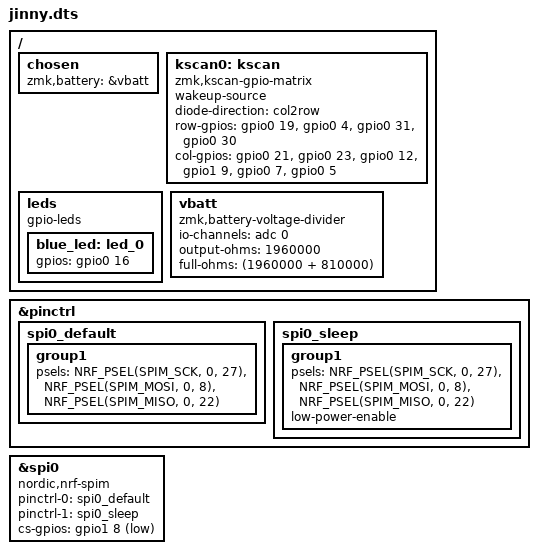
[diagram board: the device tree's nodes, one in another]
/*
*
* Copyright (c) 2021 Darryl deHaan
* SPDX-License-Identifier: MIT
*
*/

#include "jinny.dtsi"

/{
    chosen {
        zmk,battery = &vbatt;
    };

    kscan0: kscan {
        compatible = "zmk,kscan-gpio-matrix";
        wakeup-source;

        diode-direction = "col2row";
        row-gpios
            = <&gpio0 19 (GPIO_ACTIVE_HIGH | GPIO_PULL_DOWN)>
            , <&gpio0  4 (GPIO_ACTIVE_HIGH | GPIO_PULL_DOWN)>
            , <&gpio0 31 (GPIO_ACTIVE_HIGH | GPIO_PULL_DOWN)>
            , <&gpio0 30 (GPIO_ACTIVE_HIGH | GPIO_PULL_DOWN)>
            ;

        col-gpios
            = <&gpio0 21 GPIO_ACTIVE_HIGH>
            , <&gpio0 23 GPIO_ACTIVE_HIGH>
            , <&gpio0 12 GPIO_ACTIVE_HIGH>
            , <&gpio1  9 GPIO_ACTIVE_HIGH>
            , <&gpio0  7 GPIO_ACTIVE_HIGH>
            , <&gpio0  5 GPIO_ACTIVE_HIGH>
            ;
    };

    leds {
        compatible = "gpio-leds";
        blue_led: led_0 {
            gpios = <&gpio0 16 GPIO_ACTIVE_HIGH>;
        };
    };

    vbatt: vbatt {
        compatible = "zmk,battery-voltage-divider";
        io-channels = <&adc 0>;
        output-ohms = <1960000>;
        full-ohms = <(1960000 + 810000)>;
    };

};

&pinctrl {
    spi0_default: spi0_default {
        group1 {
            psels = <NRF_PSEL(SPIM_SCK, 0, 27)>,
                <NRF_PSEL(SPIM_MOSI, 0, 8)>,
                <NRF_PSEL(SPIM_MISO, 0, 22)>;
        };
    };

    spi0_sleep: spi0_sleep {
        group1 {
            psels = <NRF_PSEL(SPIM_SCK, 0, 27)>,
                <NRF_PSEL(SPIM_MOSI, 0, 8)>,
                <NRF_PSEL(SPIM_MISO, 0, 22)>;
            low-power-enable;
        };
    };
};

&spi0 {
    status = "okay";
    compatible = "nordic,nrf-spim";
    pinctrl-0 = <&spi0_default>;
    pinctrl-1 = <&spi0_sleep>;
    pinctrl-names = "default", "sleep";
    cs-gpios = <&gpio1 8 GPIO_ACTIVE_LOW>;
};
